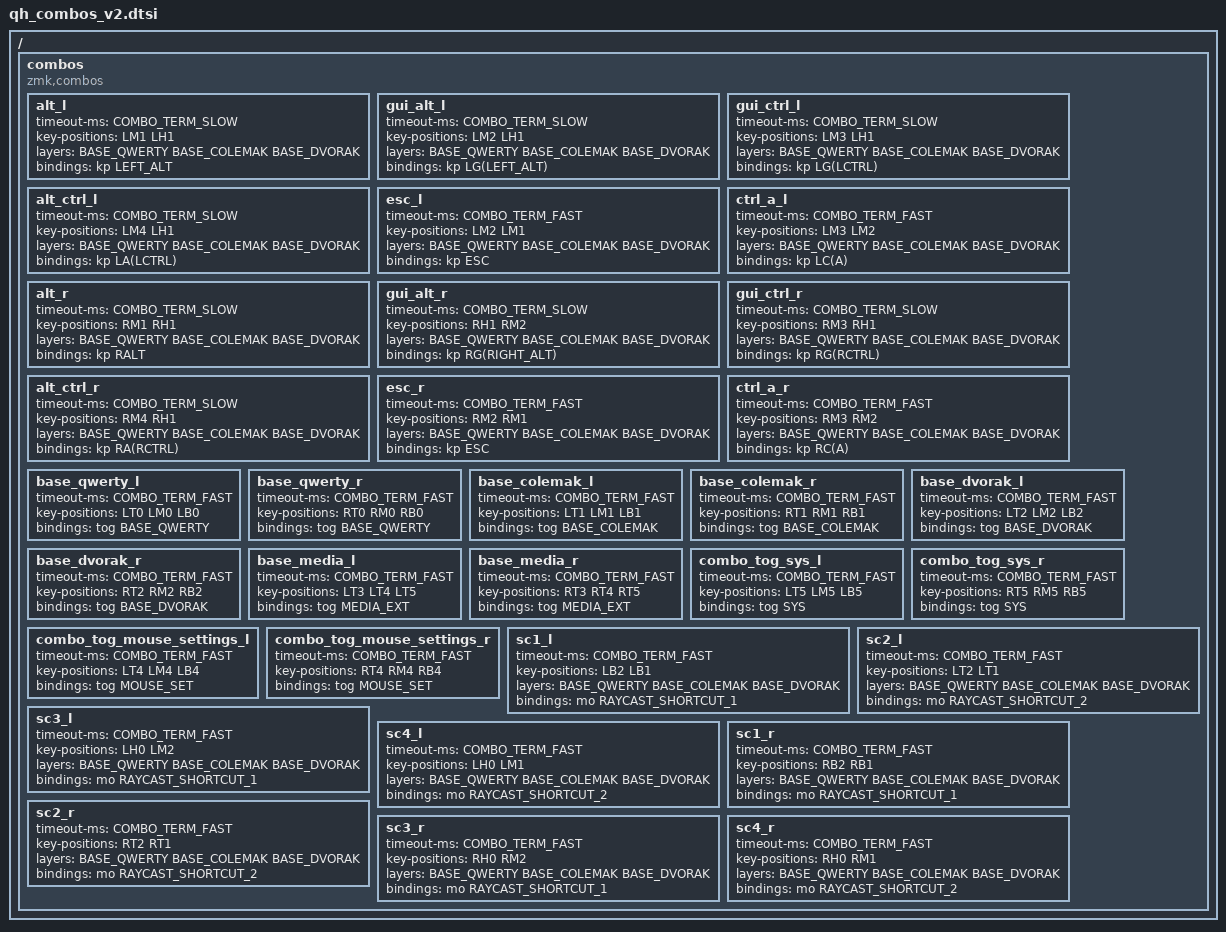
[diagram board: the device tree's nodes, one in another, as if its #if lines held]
#define COMBO_TERM_FAST 35
#define COMBO_TERM_SLOW 40
#define COMBO_PRIOR_IDLE 100

/ {
  combos {
    compatible = "zmk,combos";

    // left combos
    alt_l {
        timeout-ms = <COMBO_TERM_SLOW>;
        key-positions = <LM1 LH1>;
        layers = <BASE_QWERTY BASE_COLEMAK BASE_DVORAK>;
        bindings = <&kp LEFT_ALT>;
    };

    gui_alt_l {
        timeout-ms = <COMBO_TERM_SLOW>;
        key-positions = <LM2 LH1>;
        layers = <BASE_QWERTY BASE_COLEMAK BASE_DVORAK>;
        bindings = <&kp LG(LEFT_ALT)>;
    };


    gui_ctrl_l {
        timeout-ms = <COMBO_TERM_SLOW>;
        key-positions = <LM3 LH1>;
        layers = <BASE_QWERTY BASE_COLEMAK BASE_DVORAK>;
        bindings = <&kp  LG(LCTRL)>;
    };

    alt_ctrl_l {
        timeout-ms = <COMBO_TERM_SLOW>;
        key-positions = <LM4 LH1>;
        layers = <BASE_QWERTY BASE_COLEMAK BASE_DVORAK>;
        bindings = <&kp  LA(LCTRL)>;
    };

    esc_l {
        timeout-ms = <COMBO_TERM_FAST>;
        key-positions = <LM2 LM1>;
        layers = <BASE_QWERTY BASE_COLEMAK BASE_DVORAK>;
        bindings = <&kp ESC>;
    };

    ctrl_a_l {
        timeout-ms = <COMBO_TERM_FAST>;
        key-positions = <LM3 LM2>;
        layers = <BASE_QWERTY BASE_COLEMAK BASE_DVORAK>;
        bindings = <&kp LC(A)>;
    };

    // right combos
    alt_r {
        timeout-ms = <COMBO_TERM_SLOW>;
        key-positions = <RM1 RH1>;
        layers = <BASE_QWERTY BASE_COLEMAK BASE_DVORAK>;
        bindings = <&kp RALT>;
    };

    gui_alt_r {
        timeout-ms = <COMBO_TERM_SLOW>;
        key-positions = <RH1 RM2>;
        layers = <BASE_QWERTY BASE_COLEMAK BASE_DVORAK>;
        bindings = <&kp RG(RIGHT_ALT)>;
    };

    gui_ctrl_r {
        timeout-ms = <COMBO_TERM_SLOW>;
        key-positions = <RM3 RH1>;
        layers = <BASE_QWERTY BASE_COLEMAK BASE_DVORAK>;
        bindings = <&kp RG(RCTRL)>;
    };

    alt_ctrl_r {
        timeout-ms = <COMBO_TERM_SLOW>;
        key-positions = <RM4 RH1>;
        layers = <BASE_QWERTY BASE_COLEMAK BASE_DVORAK>;
        bindings = <&kp RA(RCTRL)>;
    };

    esc_r {
        timeout-ms = <COMBO_TERM_FAST>;
        key-positions = <RM2 RM1>;
        layers = <BASE_QWERTY BASE_COLEMAK BASE_DVORAK>;
        bindings = <&kp ESC>;
    };

    ctrl_a_r {
        timeout-ms = <COMBO_TERM_FAST>;
        key-positions = <RM3 RM2>;
        layers = <BASE_QWERTY BASE_COLEMAK BASE_DVORAK>;
        bindings = <&kp RC(A)>;
    };


    base_qwerty_l {
        timeout-ms = <COMBO_TERM_FAST>;
        key-positions = <LT0 LM0 LB0>;
        bindings = <&tog BASE_QWERTY>;
    };

    base_qwerty_r {
        timeout-ms = <COMBO_TERM_FAST>;
        key-positions = <RT0 RM0 RB0>;
        bindings = <&tog BASE_QWERTY>;
    };

    base_colemak_l {
        timeout-ms = <COMBO_TERM_FAST>;
        key-positions = <LT1 LM1 LB1>;
        bindings = <&tog BASE_COLEMAK>;
    };

    base_colemak_r {
        timeout-ms = <COMBO_TERM_FAST>;
        key-positions = <RT1 RM1 RB1>;
        bindings = <&tog BASE_COLEMAK>;
    };

    base_dvorak_l {
        timeout-ms = <COMBO_TERM_FAST>;
        key-positions = <LT2 LM2 LB2>;
        bindings = <&tog BASE_DVORAK>;
    };

    base_dvorak_r {
        timeout-ms = <COMBO_TERM_FAST>;
        key-positions = <RT2 RM2 RB2>;
        bindings = <&tog BASE_DVORAK>;
    };


    base_media_l {
        timeout-ms = <COMBO_TERM_FAST>;
        key-positions = <LT3 LT4 LT5>;
        bindings = <&tog MEDIA_EXT>;
    };

    base_media_r {
        timeout-ms = <COMBO_TERM_FAST>;
        key-positions = <RT3 RT4 RT5>;
        bindings = <&tog MEDIA_EXT>;
    };

    combo_tog_sys_l {
        timeout-ms = <COMBO_TERM_FAST>;
        key-positions = <LT5 LM5 LB5>;
        bindings = <&tog SYS>;
    };

    combo_tog_sys_r {
        timeout-ms = <COMBO_TERM_FAST>;
        key-positions = <RT5 RM5 RB5>;
        bindings = <&tog SYS>;
    };
#ifdef HAS_MOUSE_TP
    combo_tog_mouse_settings_l {
        timeout-ms = <COMBO_TERM_FAST>;
        key-positions = <LT4 LM4 LB4>;
        bindings = <&tog MOUSE_SET>;
    };

    combo_tog_mouse_settings_r {
        timeout-ms = <COMBO_TERM_FAST>;
        key-positions = <RT4 RM4 RB4>;
        bindings = <&tog MOUSE_SET>;
    };
#endif

// shortcuts

    sc1_l {
        timeout-ms = <COMBO_TERM_FAST>;
        key-positions = <LB2 LB1>;
        layers = <BASE_QWERTY BASE_COLEMAK BASE_DVORAK>;
        bindings =  <&mo RAYCAST_SHORTCUT_1>;
    };

    sc2_l {
        timeout-ms = <COMBO_TERM_FAST>;
        key-positions = <LT2 LT1>;
        layers = <BASE_QWERTY BASE_COLEMAK BASE_DVORAK>;
        bindings =  <&mo RAYCAST_SHORTCUT_2>;
    };

    sc3_l {
        timeout-ms = <COMBO_TERM_FAST>;
        key-positions = <LH0 LM2>;
        layers = <BASE_QWERTY BASE_COLEMAK BASE_DVORAK>;
        bindings =  <&mo RAYCAST_SHORTCUT_1>;
    };

    sc4_l {
        timeout-ms = <COMBO_TERM_FAST>;
        key-positions = <LH0 LM1>;
        layers = <BASE_QWERTY BASE_COLEMAK BASE_DVORAK>;
        bindings =  <&mo RAYCAST_SHORTCUT_2>;
    };

    sc1_r {
        timeout-ms = <COMBO_TERM_FAST>;
        key-positions = <RB2 RB1>;
        layers = <BASE_QWERTY BASE_COLEMAK BASE_DVORAK>;
        bindings =  <&mo RAYCAST_SHORTCUT_1>;
    };

    sc2_r {
        timeout-ms = <COMBO_TERM_FAST>;
        key-positions = <RT2 RT1>;
        layers = <BASE_QWERTY BASE_COLEMAK BASE_DVORAK>;
        bindings =  <&mo RAYCAST_SHORTCUT_2>;
    };

    sc3_r {
        timeout-ms = <COMBO_TERM_FAST>;
        key-positions = <RH0 RM2>;
        layers = <BASE_QWERTY BASE_COLEMAK BASE_DVORAK>;
        bindings =  <&mo RAYCAST_SHORTCUT_1>;
    };

    sc4_r {
        timeout-ms = <COMBO_TERM_FAST>;
        key-positions = <RH0 RM1>;
        layers = <BASE_QWERTY BASE_COLEMAK BASE_DVORAK>;
        bindings =  <&mo RAYCAST_SHORTCUT_2>;
    };

  };
};
